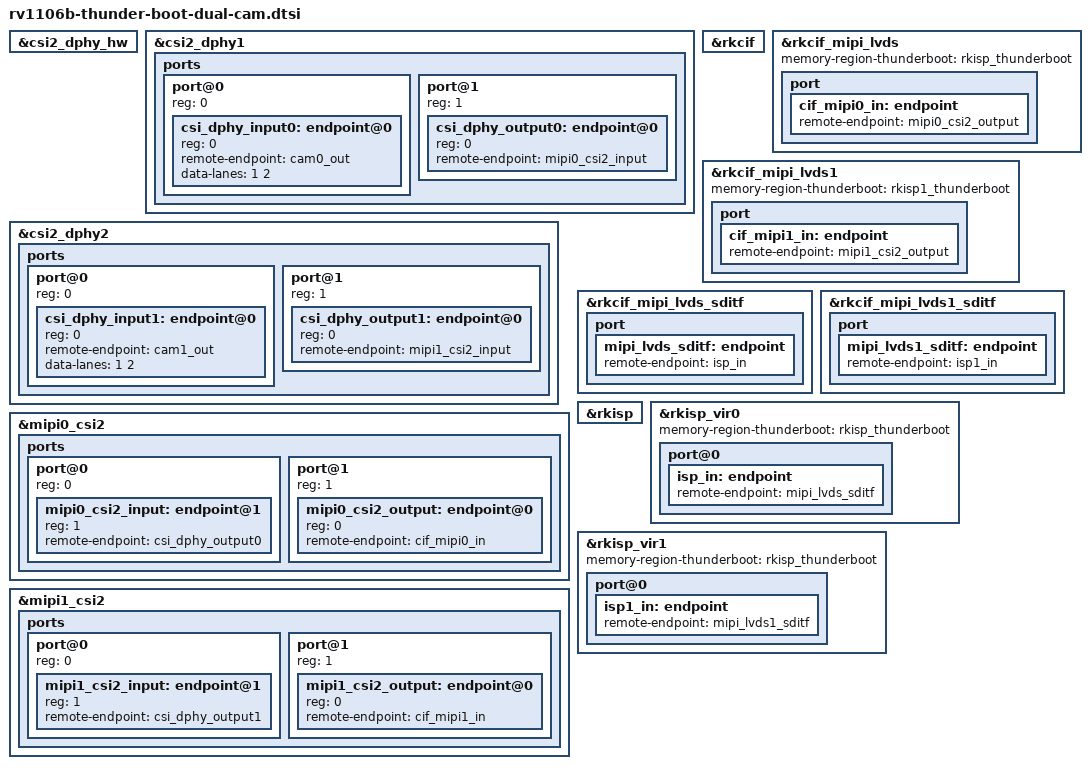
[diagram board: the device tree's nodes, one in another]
// SPDX-License-Identifier: (GPL-2.0+ OR MIT)
/*
 * Copyright (c) 2026 Rockchip Electronics Co., Ltd.
 *
 */

&csi2_dphy_hw {
	status = "okay";
};

&csi2_dphy1 {
	status = "okay";

	ports {
		#address-cells = <1>;
		#size-cells = <0>;

		port@0 {
			reg = <0>;
			#address-cells = <1>;
			#size-cells = <0>;

			csi_dphy_input0: endpoint@0 {
				reg = <0>;
				remote-endpoint = <&cam0_out>;
				data-lanes = <1 2>;
			};
		};

		port@1 {
			reg = <1>;
			#address-cells = <1>;
			#size-cells = <0>;

			csi_dphy_output0: endpoint@0 {
				reg = <0>;
				remote-endpoint = <&mipi0_csi2_input>;
			};
		};
	};
};

&csi2_dphy2 {
	status = "okay";

	ports {
		#address-cells = <1>;
		#size-cells = <0>;

		port@0 {
			reg = <0>;
			#address-cells = <1>;
			#size-cells = <0>;

			csi_dphy_input1: endpoint@0 {
				reg = <0>;
				remote-endpoint = <&cam1_out>;
				data-lanes = <1 2>;
			};
		};

		port@1 {
			reg = <1>;
			#address-cells = <1>;
			#size-cells = <0>;

			csi_dphy_output1: endpoint@0 {
				reg = <0>;
				remote-endpoint = <&mipi1_csi2_input>;
			};
		};
	};
};

&mipi0_csi2 {
	status = "okay";

	ports {
		#address-cells = <1>;
		#size-cells = <0>;

		port@0 {
			reg = <0>;
			#address-cells = <1>;
			#size-cells = <0>;

			mipi0_csi2_input: endpoint@1 {
				reg = <1>;
				remote-endpoint = <&csi_dphy_output0>;
			};
		};

		port@1 {
			reg = <1>;
			#address-cells = <1>;
			#size-cells = <0>;

			mipi0_csi2_output: endpoint@0 {
				reg = <0>;
				remote-endpoint = <&cif_mipi0_in>;
			};
		};
	};
};

&mipi1_csi2 {
	status = "okay";

	ports {
		#address-cells = <1>;
		#size-cells = <0>;

		port@0 {
			reg = <0>;
			#address-cells = <1>;
			#size-cells = <0>;

			mipi1_csi2_input: endpoint@1 {
				reg = <1>;
				remote-endpoint = <&csi_dphy_output1>;
			};
		};

		port@1 {
			reg = <1>;
			#address-cells = <1>;
			#size-cells = <0>;

			mipi1_csi2_output: endpoint@0 {
				reg = <0>;
				remote-endpoint = <&cif_mipi1_in>;
			};
		};
	};
};

&rkcif {
	status = "okay";
};

&rkcif_mipi_lvds {
	status = "okay";
	memory-region-thunderboot = <&rkisp_thunderboot>;

	port {
		/* MIPI CSI-2 endpoint */
		cif_mipi0_in: endpoint {
			remote-endpoint = <&mipi0_csi2_output>;
		};
	};
};

&rkcif_mipi_lvds1 {
	status = "okay";
	memory-region-thunderboot = <&rkisp1_thunderboot>;

	port {
		/* MIPI CSI-2 endpoint */
		cif_mipi1_in: endpoint {
			remote-endpoint = <&mipi1_csi2_output>;
		};
	};
};

&rkcif_mipi_lvds_sditf {
	status = "okay";

	port {
		/* MIPI CSI-2 endpoint */
		mipi_lvds_sditf: endpoint {
			remote-endpoint = <&isp_in>;
		};
	};
};

&rkcif_mipi_lvds1_sditf {
	status = "okay";

	port {
		/* MIPI CSI-2 endpoint */
		mipi_lvds1_sditf: endpoint {
			remote-endpoint = <&isp1_in>;
		};
	};
};

&rkisp {
	status = "okay";
};

&rkisp_vir0 {
	status = "okay";
	memory-region-thunderboot = <&rkisp_thunderboot>;

	port@0 {
		isp_in: endpoint {
			remote-endpoint = <&mipi_lvds_sditf>;
		};
	};
};

&rkisp_vir1 {
	status = "okay";
	memory-region-thunderboot = <&rkisp_thunderboot>;

	port@0 {
		isp1_in: endpoint {
			remote-endpoint = <&mipi_lvds1_sditf>;
		};
	};
};
